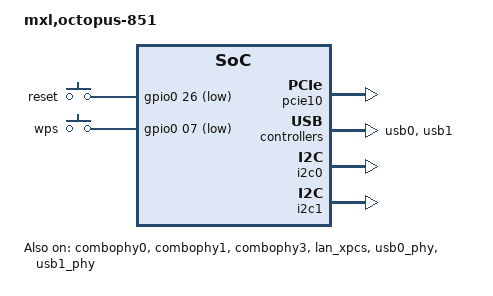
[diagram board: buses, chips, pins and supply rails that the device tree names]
// SPDX-License-Identifier: GPL-2.0
/*
 * Copyright (C) 2023 MaxLinear, Inc.
 */
#include <dt-bindings/input/input.h>
#include "octopus_851.dtsi"

/******************************************************************************
** Board configuration: Enable buttons on the board.
******************************************************************************/
/ {
	gpio-keys-polled {
		compatible = "gpio-keys-polled";
		#address-cells = <1>;
		#size-cells = <0>;
		poll-interval = <100>;

		reset {
			label = "reset";
			gpios = <&gpio0 26 1>;
			linux,code = <KEY_RESTART>;
		};
		wps {
			label = "wps";
			gpios = <&gpio0 07 1>;
			linux,code = <KEY_WPS_BUTTON>;
		};
	};
};


/ {
	model = "mxl,octopus-851";

	chosen {
		/* ramfs */
		bootargs = "earlycon console=ttyLTQ0,115200n8r root=/dev/ram init=/init maxcpus=4 initcall_debug=0 clk_ignore_unused loglevel=8";
		stdout-path = "serial0";
	};
};


/* combo PHY setting */
/* combo phy 0 */
&combophy0 { /* PCIe10/11, HSIOL_XPCS0/1, SATA10/11 */ 
	status = "okay";
};

/* combo phy 1 */
&combophy1 { /* PCIe30/31 */
	status = "okay";
};

/* combo phy 3 */
&combophy3 { /* PCIE40/41 */
	status = "okay";
};

/* Enable P34x */
&lan_xpcs {
	status = "okay";
};

 /* PCIe */
&pcie10 {
	status = "okay";
};

&pcie30 {
	status = "disabled";
};

&pcie40 {
	status = "disabled";
};

&usb0_phy {
	status = "okay";
	vbus-supply = <&usb_vbus>;
	extcon = <&ptn5150_1>;
};

&usb0 {
	status = "okay";
};

&usb1_phy {
	status = "okay";
	vbus-supply = <&usb_vbus>;
};

&usb1 {
	status = "okay";
};

&i2c0 { /* used by PMIC */
	status = "okay";
};

&i2c1 { /* used by USB type-C */
	status = "okay";
};

